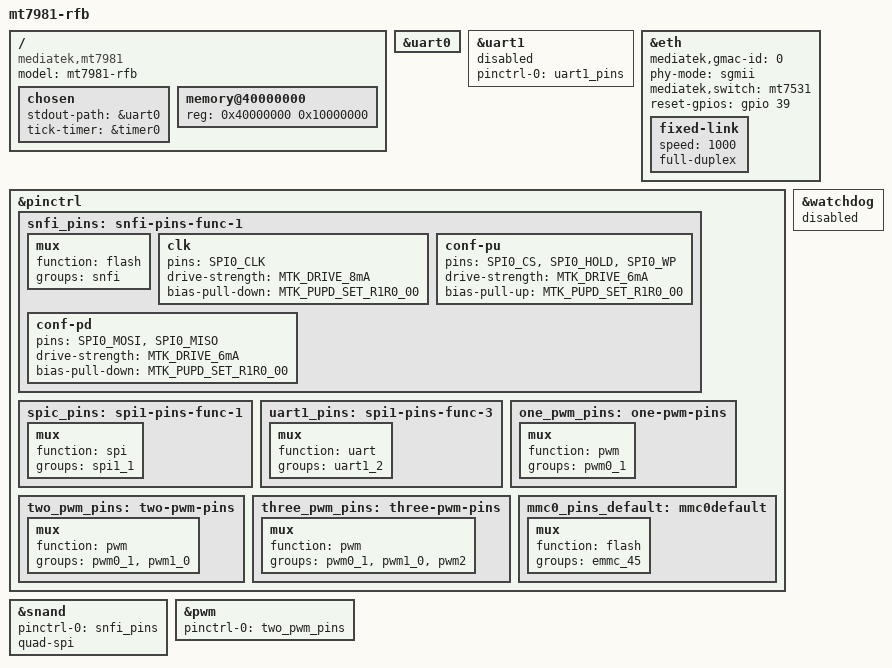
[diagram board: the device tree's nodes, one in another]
// SPDX-License-Identifier: GPL-2.0
/*
 * Copyright (c) 2021 MediaTek Inc.
 * Author: Sam Shih <sam.shih@mediatek.com>
 */

/dts-v1/;
#include "mt7981.dtsi"
#include <dt-bindings/gpio/gpio.h>

/ {
	#address-cells = <1>;
	#size-cells = <1>;
	model = "mt7981-rfb";
	compatible = "mediatek,mt7981", "mediatek,mt7981-rfb";
	chosen {
		stdout-path = &uart0;
		tick-timer = &timer0;
	};

	memory@40000000 {
		device_type = "memory";
		reg = <0x40000000 0x10000000>;
	};
};

&uart0 {
	status = "okay";
};

&uart1 {
	pinctrl-names = "default";
	pinctrl-0 = <&uart1_pins>;
	status = "disabled";
};

&eth {
	status = "okay";
	mediatek,gmac-id = <0>;
	phy-mode = "sgmii";
	mediatek,switch = "mt7531";
	reset-gpios = <&gpio 39 GPIO_ACTIVE_HIGH>;

	fixed-link {
		speed = <1000>;
		full-duplex;
	};
};

&pinctrl {
	snfi_pins: snfi-pins-func-1 {
		mux {
			function = "flash";
			groups = "snfi";
		};

		clk {
			pins = "SPI0_CLK";
			drive-strength = <MTK_DRIVE_8mA>;
			bias-pull-down = <MTK_PUPD_SET_R1R0_00>;
		};

		conf-pu {
			pins = "SPI0_CS", "SPI0_HOLD", "SPI0_WP";
			drive-strength = <MTK_DRIVE_6mA>;
			bias-pull-up = <MTK_PUPD_SET_R1R0_00>;
		};

		conf-pd {
			pins = "SPI0_MOSI", "SPI0_MISO";
			drive-strength = <MTK_DRIVE_6mA>;
			bias-pull-down = <MTK_PUPD_SET_R1R0_00>;
		};
	};

	spic_pins: spi1-pins-func-1 {
		mux {
			function = "spi";
			groups = "spi1_1";
		};
	};

	uart1_pins: spi1-pins-func-3 {
		mux {
			function = "uart";
			groups = "uart1_2";
		};
	};

	/* pin15 as pwm0 */
	one_pwm_pins: one-pwm-pins {
		mux {
			function = "pwm";
			groups = "pwm0_1";
		};
	};

	/* pin15 as pwm0 and pin14 as pwm1 */
	two_pwm_pins: two-pwm-pins {
		mux {
			function = "pwm";
			groups = "pwm0_1", "pwm1_0";
		};
	};

	/* pin15 as pwm0, pin14 as pwm1, pin7 as pwm2 */
	three_pwm_pins: three-pwm-pins {
		mux {
			function = "pwm";
			groups = "pwm0_1", "pwm1_0", "pwm2";
		};
	};

	mmc0_pins_default: mmc0default {
                mux {
                       function = "flash";
                       groups =  "emmc_45";
                 };
         };
};

&snand {
	pinctrl-names = "default";
	pinctrl-0 = <&snfi_pins>;
	status = "okay";
	quad-spi;
};

&pwm {
	pinctrl-names = "default";
	pinctrl-0 = <&two_pwm_pins>;
	status = "okay";
};

&watchdog {
	status = "disabled";
};
